# RTC register map
Vendor: Texas Instruments
Peripheral module from a debugger description file (folder ucd3138128).
Registers are 32-bit, access not given, no defined reset value unless marked. A register's access mark holds for its fields unless they carry their own. Offsets are as the file gives them; lines under a group give offsets from that group; [hi:lo] are bit positions; {n}, {i} and the like mark numbered series; 'fields as' and 'values as' point back to an identical list; <NAME> marks a mode.

## RTC
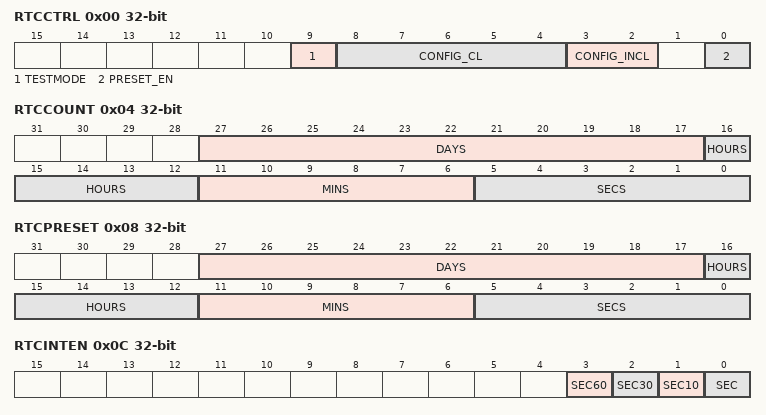
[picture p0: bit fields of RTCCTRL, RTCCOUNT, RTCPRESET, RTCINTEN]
0x00 RTCCTRL — RTC Control Register
  [9] TESTMODE rw
  [8:4] CONFIG_CL rw — Analog config cl
  [3:2] CONFIG_INCL rw — Analog config incl
  [0] PRESET_EN rw — Preset enable
0x04 RTCCOUNT
  [27:17] DAYS ro — Count days
  [16:12] HOURS ro — Count hours
  [11:6] MINS ro — Count minutes
  [5:0] SECS ro — Count seconds
0x08 RTCPRESET — RTC Count Preset Register
  [27:17] DAYS rw — Preset days
  [16:12] HOURS rw — Preset hours
  [11:6] MINS rw — Preset minutes
  [5:0] SECS rw — Preset seconds
0x0C RTCINTEN — RTC Interrupt Enable Register
  [3] SEC60 rw — 60sec interrupt en
  [2] SEC30 rw — 30sec interrupt en
  [1] SEC10 rw — 10sec interrupt en
  [0] SEC rw — 1sec interrupt en
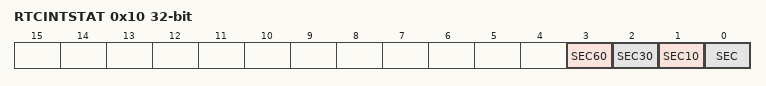
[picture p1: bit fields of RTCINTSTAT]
0x10 RTCINTSTAT — RTC Interrupt Status Register
  [3] SEC60 ro — 60sec interrupt en
  [2] SEC30 ro — 30sec interrupt en
  [1] SEC10 ro — 10sec interrupt en
  [0] SEC ro — 1sec interrupt en
0x14 RTCPRESCALE
  [9:0] PRESCALE rw — Prescaler value
